# dbb_tx register map
Registers are 16-bit, access not given, no defined reset value unless marked. A register's access mark holds for its fields unless they carry their own. Offsets are from the block's base; lines under a group give offsets from that group; [hi:lo] are bit positions; {n}, {i} and the like mark numbered series; 'fields as' and 'values as' point back to an identical list; <NAME> marks a mode.

## Memory map
? dbb_tx — PAN2G TX Config

## dbb_tx — PAN2G TX Config
Base ?
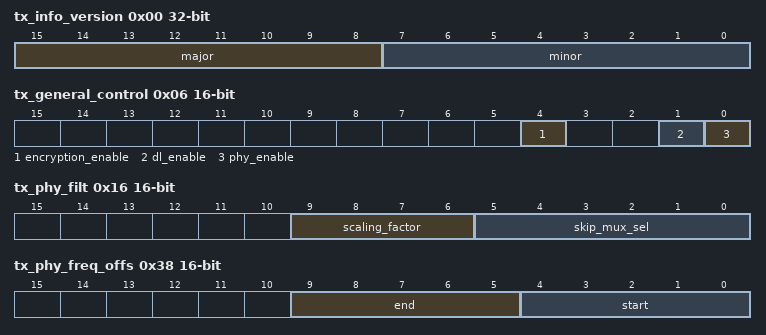
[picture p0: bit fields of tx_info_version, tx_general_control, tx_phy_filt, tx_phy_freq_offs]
0x00 tx_info_version 32-bit — version
  [15:8] major — Version major part
  [7:0] minor — Version minor part
0x04 tx_general_standard — Standard: 1 = Zigbee (15.4), 2 = BAN (15.6), 3 = Bluetooth Low Energy (BTLE)
  [1:0] standard — Wireless standard to use.
    1=Zigbee (15.4); 2=ban (BAN (15.6).); 3=BTLE (Bluetooth Low Energy (BTLE).)
0x06 tx_general_control — control
  [4] encryption_enable — Enable the link layer encryption.
  [1] dl_enable — Enable the datalink layer of the tramsitter
  [0] phy_enable — Enable the PHY layer of the transmitter
0x08 tx_general_send_multi 32-bit — Enable the sending of a single frame multiple times. Without writing again the payload data neither the PHY header.
0x0C tx_phy_high_freq_coef — Multiplier for DAC frequency output
0x0E tx_phy_low_freq_coef — Multiplier for programmable divider frequency output
0x10 tx_phy_freq_carrier 32-bit — Carrier frequency
0x14 tx_phy_amp_coef — Amplitude coefficient
0x16 tx_phy_filt — filt
  [9:6] scaling_factor — Number of bits that filter output must be shifted right
  [5:0] skip_mux_sel — Filter length selection. When bit x is 1, data is input after 3x taps, effectively bypassing them.
{0x18+2i} tx_phy_filt_coefs[{i}] (i=0..15) — Filter coefficients
0x38 tx_phy_freq_offs — freq_offs
  [9:5] end — Number of frequency samples to be skipped at end of output
  [4:0] start — Number of frequency samples to be skipped at start of output
0x3A tx_phy_ovrsamp_ratio — Oversampling ratio
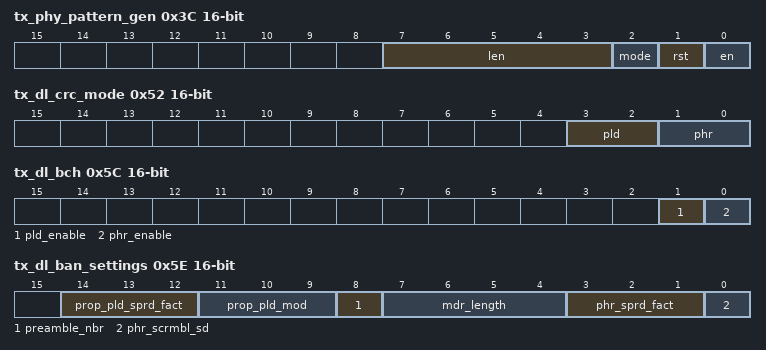
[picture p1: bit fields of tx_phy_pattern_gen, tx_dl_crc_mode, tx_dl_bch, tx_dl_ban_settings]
0x3C tx_phy_pattern_gen — pattern_gen
  [7:3] len — Length of pattern in bits
  [2] mode — Pattern generation mode: 0 = PRBS, 1 = user pattern
    0=prbs; 1=user
  [1] rst — Reset pattern generator (needed after generator configuration change)
  [0] en — Enable pattern generator
0x3E tx_phy_pattern — Mode 0: generator polynomial, mode 1: user pattern
0x40 tx_phy_const_output_enable — const_output_enable
0x42 tx_phy_const_output_amp — Constant value for amplitude output
0x44 tx_phy_const_output_freq_high 32-bit — Constant value for DAC frequency output
0x48 tx_phy_const_output_freq_low 32-bit — Constant value for programmable divider frequency output
0x4C tx_dbg_dl_lb 32-bit — The datalink Loop back is enabled. In this mode the datalink transmitter layer is connected to the datalink receiver layer (the transmitter and the receiver PHY layer are bypassed)
0x50 tx_dl_bypass — Bypass the datalink layer. When this bit is set the frame (preamble data + header data + payload data) is sent directly to the PHY layer.
0x52 tx_dl_crc_mode — crc_mode
  [3:2] pld — Payload CRC type: 0 = data bypassed, 1 = CRC-4, 2= CRC-16, 3 = CRC-24
    0=byp (data bypassed.); 1=crc4; 2=crc16; 3=crc24
  [1:0] phr — Header CRC type: 0 = data bypassed, 1 = CRC-4, 2 = CRC-16, 3 = CRC-24
    0=byp (data bypassed.); 1=crc4; 2=crc16; 3=crc24
0x54 tx_dl_crc_init_phr 32-bit — CRC LFSR initialization value for the header
0x58 tx_dl_crc_init_pld 32-bit — CRC LFSR initialization value for the payload
0x5C tx_dl_bch — bch
  [1] pld_enable — BCH encode enabled on the payload
  [0] phr_enable — BCH encode enabled on the header
0x5E tx_dl_ban_settings — ban_settings
  [14:12] prop_pld_sprd_fact — Proprietary mode payload spread factor: 1 = sprd_fact_1, 2 = sprd_fact_2, 3 = sprd_fact_4, 4 = sprd_fact_8, 5 = sprd_fact_16
    1=sprd_fact_1; 2=sprd_fact_2; 3=sprd_fact_4; 4=sprd_fact_8; 5=sprd_fact_16
  [11:9] prop_pld_mod — Proprietary mode payload modulation: OQPSK=0, 1 = DBPSK 2 = DQPSK, 3 = D8PSK, 4 = GMSK, 5 = GFSK
    0=OQPSK; 1=DBPSK; 2=DQPSK; 3=D8PSK; 4=GMSK; 5=GFSK
  [8] preamble_nbr — The preamble number; this parameter is used in the 15.6 standard to choose between the 2 preamble data (please refer to the standard)
  [7:4] mdr_length — MAC header length in bytes
  [3:1] phr_sprd_fact — Header spread factor: 1 = sprd_fact_1, 2 = sprd_fact_2, 3 = sprd_fact_4, 4 = sprd_fact_8, 5 = sprd_fact_16
    values as prop_pld_sprd_fact
  [0] phr_scrmbl_sd — Header scrambler seed, used to initialize the LFSR of the scrambler module when processing the header
0x60 tx_dl_btle_settings_adv_acc_addr 32-bit — Advertisement channel access address used to determine if frame is for advertisement channel
0x64 tx_dl_btle_settings_acc_addr 32-bit — Access addres that is transmitted
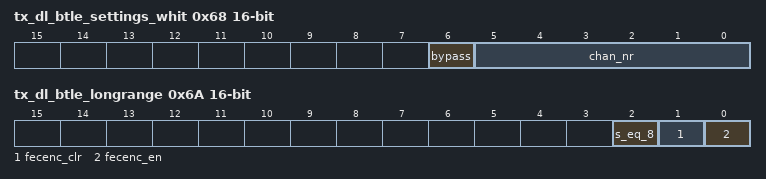
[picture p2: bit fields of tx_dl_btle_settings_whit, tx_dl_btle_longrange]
0x68 tx_dl_btle_settings_whit — btle_settings_whit
  [6] bypass — Whitening bypass enable
  [5:0] chan_nr — Channel number used dewhitening
0x6A tx_dl_btle_longrange — btle_longrange
  [2] s_eq_8 — If set to '1' and Fec encoder is enabled; S=8, if set to '0' and Fec encoder is enabled => S=2
    1=S8; 0=S2
  [1] fecenc_clr — If '1' is written Fec encoder delay line will be set to '0'.
  [0] fecenc_en — If '1' Fec encoding is enabled, if '0' Fec encoding is in bypass
0x6C tx_dl_phr_modulation — Header modulation: OQPSK=0, 1 = DBPSK 2 = DQPSK, 3 = D8PSK, 4 = GMSK, 5 = GFSK
  [2:0] mod — modulation.
    0=OQPSK; 1=DBPSK; 2=DQPSK; 3=D8PSK; 4=GMSK; 5=GFSK
0x6E tx_dl_phr — Multi-standard PHY header (setting rate to 4 for the BAN standards results in the proprietary mode being used)
{0x70+4i} tx_pld_mem[{i}] (i=0..65) 32-bit — Payload memory: 66 address
0x178 tx_dl2_btle_speed_mode — Set BTLE speed mode 0 = 1 Mb/s, 1 = 2 Mb/s
  [0] speed
    0=1M; 1=2M
